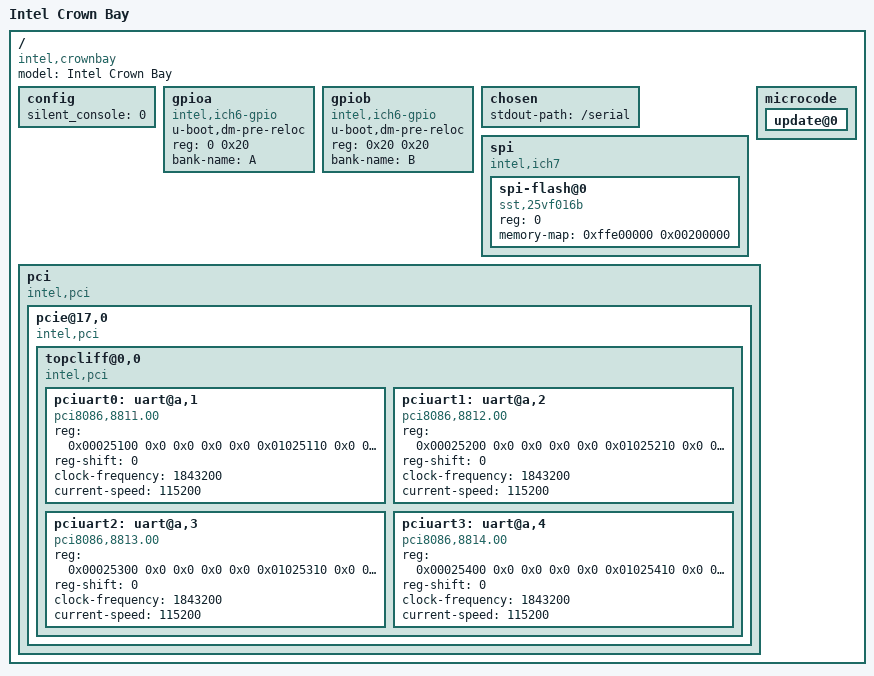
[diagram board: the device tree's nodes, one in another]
/*
 * Copyright (C) 2014, Bin Meng <bmeng.cn@gmail.com>
 *
 * SPDX-License-Identifier:	GPL-2.0+
 */

/dts-v1/;

/include/ "skeleton.dtsi"
/include/ "serial.dtsi"

/ {
	model = "Intel Crown Bay";
	compatible = "intel,crownbay", "intel,queensbay";

	config {
		silent_console = <0>;
	};

	gpioa {
		compatible = "intel,ich6-gpio";
		u-boot,dm-pre-reloc;
		reg = <0 0x20>;
		bank-name = "A";
	};

	gpiob {
		compatible = "intel,ich6-gpio";
		u-boot,dm-pre-reloc;
		reg = <0x20 0x20>;
		bank-name = "B";
	};

	chosen {
		/*
		 * By default the legacy superio serial port is used as the
		 * U-Boot serial console. If we want to use UART from Topcliff
		 * PCH as the console, change this property to &pciuart#.
		 *
		 * For example, stdout-path = &pciuart0 will use the first
		 * UART on Topcliff PCH.
		 */
		stdout-path = "/serial";
	};

	spi {
		#address-cells = <1>;
		#size-cells = <0>;
		compatible = "intel,ich7";
		spi-flash@0 {
			reg = <0>;
			compatible = "sst,25vf016b", "spi-flash";
			memory-map = <0xffe00000 0x00200000>;
		};
	};

	microcode {
		update@0 {
#include "microcode/m0220661105_cv.dtsi"
		};
	};

	pci {
		#address-cells = <3>;
		#size-cells = <2>;
		compatible = "intel,pci";
		device_type = "pci";

		pcie@17,0 {
			#address-cells = <3>;
			#size-cells = <2>;
			compatible = "intel,pci";
			device_type = "pci";

			topcliff@0,0 {
				#address-cells = <3>;
				#size-cells = <2>;
				compatible = "intel,pci";
				device_type = "pci";

				pciuart0: uart@a,1 {
					compatible = "pci8086,8811.00",
							"pci8086,8811",
							"pciclass,070002",
							"pciclass,0700",
							"x86-uart";
					reg = <0x00025100 0x0 0x0 0x0 0x0
					       0x01025110 0x0 0x0 0x0 0x0>;
					reg-shift = <0>;
					clock-frequency = <1843200>;
					current-speed = <115200>;
				};

				pciuart1: uart@a,2 {
					compatible = "pci8086,8812.00",
							"pci8086,8812",
							"pciclass,070002",
							"pciclass,0700",
							"x86-uart";
					reg = <0x00025200 0x0 0x0 0x0 0x0
					       0x01025210 0x0 0x0 0x0 0x0>;
					reg-shift = <0>;
					clock-frequency = <1843200>;
					current-speed = <115200>;
				};

				pciuart2: uart@a,3 {
					compatible = "pci8086,8813.00",
							"pci8086,8813",
							"pciclass,070002",
							"pciclass,0700",
							"x86-uart";
					reg = <0x00025300 0x0 0x0 0x0 0x0
					       0x01025310 0x0 0x0 0x0 0x0>;
					reg-shift = <0>;
					clock-frequency = <1843200>;
					current-speed = <115200>;
				};

				pciuart3: uart@a,4 {
					compatible = "pci8086,8814.00",
							"pci8086,8814",
							"pciclass,070002",
							"pciclass,0700",
							"x86-uart";
					reg = <0x00025400 0x0 0x0 0x0 0x0
					       0x01025410 0x0 0x0 0x0 0x0>;
					reg-shift = <0>;
					clock-frequency = <1843200>;
					current-speed = <115200>;
				};
			};
		};
	};

};
